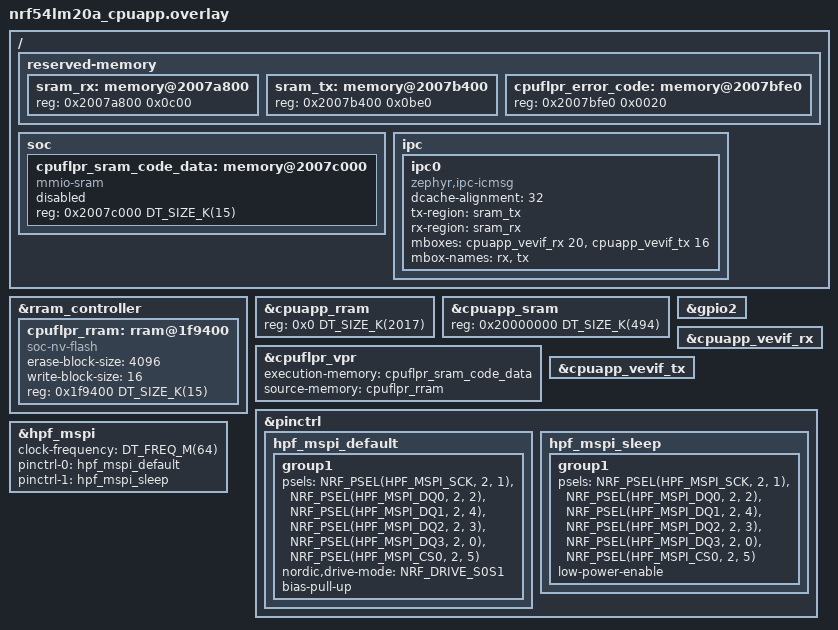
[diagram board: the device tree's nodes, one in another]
/*
 * Copyright (c) 2025 Nordic Semiconductor ASA
 *
 * SPDX-License-Identifier: LicenseRef-Nordic-5-Clause
 */

/ {
	reserved-memory {
		#address-cells = <1>;
		#size-cells = <1>;

		sram_rx: memory@2007a800 {
			reg = <0x2007a800 0x0c00>;
		};

		sram_tx: memory@2007b400 {
			reg = <0x2007b400 0x0be0>;
		};

		cpuflpr_error_code: memory@2007bfe0 {
			reg = <0x2007bfe0 0x0020>; /* 32bytes */
		};
	};

	soc {
		cpuflpr_sram_code_data: memory@2007c000 {
			compatible = "mmio-sram";
			reg = <0x2007c000 DT_SIZE_K(15)>;
			#address-cells = <1>;
			#size-cells = <1>;
			ranges = <0x0 0x2007c000 DT_SIZE_K(15)>;
			status = "reserved";
		};
	};

	ipc {
		ipc0: ipc0 {
			compatible = "zephyr,ipc-icmsg";
			dcache-alignment = <32>;
			tx-region = <&sram_tx>;
			rx-region = <&sram_rx>;
			mboxes = <&cpuapp_vevif_rx 20>, <&cpuapp_vevif_tx 16>;
			mbox-names = "rx", "tx";
			status = "okay";
		};
	};
};

&rram_controller {
	cpuflpr_rram: rram@1f9400 {
		compatible = "soc-nv-flash";
		erase-block-size = <4096>;
		write-block-size = <16>;
		reg = <0x1f9400 DT_SIZE_K(15)>;
		ranges = <0x0 0x1f9400 DT_SIZE_K(15)>;
		#address-cells = <1>;
		#size-cells = <1>;
	};
};

&cpuapp_rram {
	reg = <0x0 DT_SIZE_K(2017)>;
	ranges = <0x0 0x0 DT_SIZE_K(2017)>;
	#address-cells = <1>;
	#size-cells = <1>;
};

&cpuapp_sram {
	reg = <0x20000000 DT_SIZE_K(494)>;
	ranges = <0x0 0x20000000 DT_SIZE_K(494)>;
};

&cpuflpr_vpr {
	execution-memory = <&cpuflpr_sram_code_data>;
	source-memory = <&cpuflpr_rram>;
};

&gpio2 {
	status = "okay";
};

&cpuapp_vevif_rx {
	status = "okay";
};

&cpuapp_vevif_tx {
	status = "okay";
};

&pinctrl {
	/omit-if-no-ref/ hpf_mspi_default: hpf_mspi_default {
		group1 {
			psels = <NRF_PSEL(HPF_MSPI_SCK, 2, 1)>,
				<NRF_PSEL(HPF_MSPI_DQ0, 2, 2)>,
				<NRF_PSEL(HPF_MSPI_DQ1, 2, 4)>,
				<NRF_PSEL(HPF_MSPI_DQ2, 2, 3)>,
				<NRF_PSEL(HPF_MSPI_DQ3, 2, 0)>,
				<NRF_PSEL(HPF_MSPI_CS0, 2, 5)>;
			nordic,drive-mode = <NRF_DRIVE_S0S1>;
			bias-pull-up;
		};
	};

	/omit-if-no-ref/ hpf_mspi_sleep: hpf_mspi_sleep {
		group1 {
			psels = <NRF_PSEL(HPF_MSPI_SCK, 2, 1)>,
				<NRF_PSEL(HPF_MSPI_DQ0, 2, 2)>,
				<NRF_PSEL(HPF_MSPI_DQ1, 2, 4)>,
				<NRF_PSEL(HPF_MSPI_DQ2, 2, 3)>,
				<NRF_PSEL(HPF_MSPI_DQ3, 2, 0)>,
				<NRF_PSEL(HPF_MSPI_CS0, 2, 5)>;
			low-power-enable;
		};
	};
};

&hpf_mspi {
	clock-frequency = <DT_FREQ_M(64)>;
	pinctrl-0 = <&hpf_mspi_default>;
	pinctrl-1 = <&hpf_mspi_sleep>;
	pinctrl-names = "default", "sleep";
	status = "okay";
};
